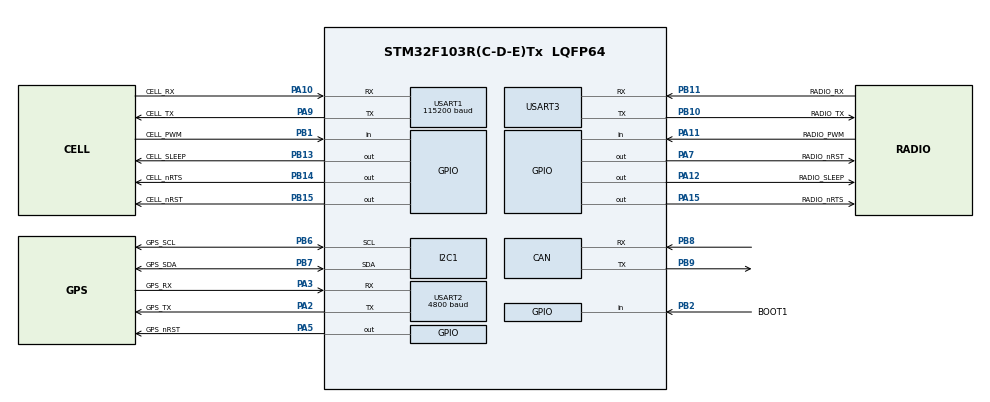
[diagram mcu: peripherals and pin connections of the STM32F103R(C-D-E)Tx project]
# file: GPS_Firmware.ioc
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CAN.CalculateTimeBit=6000
CAN.CalculateTimeQuantum=2000.0
I2C1.DualAddressMode=I2C_DUALADDRESS_DISABLE
Mcu.Family=STM32F1
Mcu.Name=STM32F103R(C-D-E)Tx
Mcu.Package=LQFP64
NVIC.PriorityGroup=NVIC_PRIORITYGROUP_4
PA10.GPIO_Label=CELL_RX
PA10.Mode=Asynchronous
PA10.Signal=USART1_RX
PA11.GPIO_Label=RADIO_PWM
PA11.Signal=GPIO_Input
PA12.GPIO_Label=RADIO_SLEEP
PA12.Signal=GPIO_Output
PA13.GPIO_Label=SWDIO
PA13.Mode=Serial_Wire
PA13.Signal=SYS_JTMS-SWDIO
PA14.GPIO_Label=SWDCLK
PA14.Mode=Serial_Wire
PA14.Signal=SYS_JTCK-SWCLK
PA15.GPIO_Label=RADIO_nRTS
PA15.Signal=GPIO_Output
PA2.GPIO_Label=GPS_TX
PA2.Mode=Asynchronous
PA2.Signal=USART2_TX
PA3.GPIO_Label=GPS_RX
PA3.Mode=Asynchronous
PA3.Signal=USART2_RX
PA5.GPIO_Label=GPS_nRST
PA5.Signal=GPIO_Output
PA7.GPIO_Label=RADIO_nRST
PA7.Signal=GPIO_Output
PA9.GPIO_Label=CELL_TX
PA9.Mode=Asynchronous
PA9.Signal=USART1_TX
PB1.GPIO_Label=CELL_PWM
PB1.Signal=GPIO_Input
PB10.GPIO_Label=RADIO_TX
PB10.Mode=Asynchronous
PB10.Signal=USART3_TX
PB11.GPIO_Label=RADIO_RX
PB11.Mode=Asynchronous
PB11.Signal=USART3_RX
PB13.GPIO_Label=CELL_SLEEP
PB13.Signal=GPIO_Output
PB14.GPIO_Label=CELL_nRTS
PB14.Signal=GPIO_Output
PB15.GPIO_Label=CELL_nRST
PB15.Signal=GPIO_Output
PB2.GPIO_Label=BOOT1
PB2.Signal=GPIO_Input
PB6.GPIO_Label=GPS_SCL
PB6.Mode=I2C
PB6.Signal=I2C1_SCL
PB7.GPIO_Label=GPS_SDA
PB7.Mode=I2C
PB7.Signal=I2C1_SDA
PB8.Mode=Master
PB8.Signal=CAN_RX
PB9.Mode=Master
PB9.Signal=CAN_TX
PC14-OSC32_IN.Signal=RCC_OSC32_IN
PC15-OSC32_OUT.Signal=RCC_OSC32_OUT
PD0-OSC_IN.Signal=RCC_OSC_IN
PD1-OSC_OUT.Signal=RCC_OSC_OUT
ProjectManager.HeapSize=0x200
ProjectManager.StackSize=0x400
ProjectManager.TargetToolchain=STM32CubeIDE
RCC.APB1Freq_Value=8000000
RCC.APB2Freq_Value=8000000
USART1.BaudRate=115200
USART1.Mode=MODE_TX_RX
USART1.StopBits=STOPBITS_1
USART1.VirtualMode=VM_ASYNC
USART1.WordLength=WORDLENGTH_8B
USART2.BaudRate=4800
USART2.VirtualMode=VM_ASYNC
USART2.WordLength=WORDLENGTH_8B
USART3.VirtualMode=VM_ASYNC
board=custom

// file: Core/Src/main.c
/* USER CODE BEGIN Header */
/**
  ******************************************************************************
  * @file           : main.c
  * @brief          : Main program body
  ******************************************************************************
  * @attention
  *
  * <h2><center>&copy; Copyright (c) 2021 STMicroelectronics.
  * All rights reserved.</center></h2>
  *
  * This software component is licensed by ST under BSD 3-Clause license,
  * the "License"; You may not use this file except in compliance with the
  * License. You may obtain a copy of the License at:
  *                        opensource.org/licenses/BSD-3-Clause
  *
  ******************************************************************************
  */
/* USER CODE END Header */
#include "main.h"
#include "stdio.h"
#include "string.h"
#include "stdbool.h"
#include "time.h"

CAN_HandleTypeDef hcan;

I2C_HandleTypeDef hi2c1;

UART_HandleTypeDef huart1;
UART_HandleTypeDef huart2;
UART_HandleTypeDef huart3;

/* USER CODE BEGIN PV */
CAN_RxHeaderTypeDef rxheader; //header for message reception
HAL_StatusTypeDef send_ret; //status return for CAN transmit

uint8_t CAN_buffer; // CAN buffer
uint8_t UART_buffer; // UART buffer

/* USER CODE END PV */

void SystemClock_Config(void);
static void MX_GPIO_Init(void);
static void MX_CAN_Init(void);
static void MX_I2C1_Init(void);
static void MX_USART1_UART_Init(void);
static void MX_USART2_UART_Init(void);
static void MX_USART3_UART_Init(void);

int main(void)
{

  /* MCU Configuration--------------------------------------------------------*/

  /* Reset of all peripherals, Initializes the Flash interface and the Systick. */
  HAL_Init();

  /* Configure the system clock */
  SystemClock_Config();

  /* Initialize all configured peripherals */
  MX_GPIO_Init();
  MX_CAN_Init();
  MX_I2C1_Init();
  MX_USART1_UART_Init();
  MX_USART2_UART_Init();
  MX_USART3_UART_Init();

  /* USER CODE BEGIN 2 */
  int can_counter;
  int timer_counter;
  time_t start_time = time(NULL); //get start time
  time_t current_time;
  timer_counter = 0;

  /* USER CODE END 2 */

  /* Infinite loop */
  while (1)
  {
    can_counter = 0;
	  //monitor CAN FIFO -> if messages, empty 3 messages from FIFO *dependent on timing/how many messages are expected*
	  while(can_counter < MAX_CAN_MESSAGES) //get CAN data
	  {
		  can_Process(&hcan,&CAN.r.rxheader,CAN.r.ret);
		  if (CAN.msgpointer != NULL)
		  {
			  xbee_Process(&huart3,&CAN.msgpointer);
			  xbee_Process(&huart1,&CAN.msgpointer);
		  }
		  else{break;}
	  }
	  //AMU
	  if(time(NULL) >= start_time+1000) //every 1 second
	  {
		  //receive AMU data
		  xbee_Process(&huart3,&CAN.msgpointer); //change to AMU data pointer
		  xbee_Process(&huart1,&CAN.msgpointer); //change to AMU data pointer
      start_time = time(NULL);
      timer_counter++;
	  }

    //GPS receive and transmit - sample every 1min *dependent on time it takes to get data/timing of CAN block*
    if(timer_counter >= 6)
    {
      gps_Init(&huart2);
      gps_Process(&huart2);
      xbee_Process(&huart3,&GPS.to_output);
      xbee_Process(&huart1,&GPS.to_output);
      timer_counter = 0;
    }

  }
}

void SystemClock_Config(void)
{
  RCC_OscInitTypeDef RCC_OscInitStruct = {0};
  RCC_ClkInitTypeDef RCC_ClkInitStruct = {0};

  /** Initializes the RCC Oscillators according to the specified parameters
  * in the RCC_OscInitTypeDef structure.
  */
  RCC_OscInitStruct.OscillatorType = RCC_OSCILLATORTYPE_HSI;
  RCC_OscInitStruct.HSIState = RCC_HSI_ON;
  RCC_OscInitStruct.HSICalibrationValue = RCC_HSICALIBRATION_DEFAULT;
  RCC_OscInitStruct.PLL.PLLState = RCC_PLL_NONE;
  if (HAL_RCC_OscConfig(&RCC_OscInitStruct) != HAL_OK)
  {
    Error_Handler();
  }
  /** Initializes the CPU, AHB and APB buses clocks
  */
  RCC_ClkInitStruct.ClockType = RCC_CLOCKTYPE_HCLK|RCC_CLOCKTYPE_SYSCLK
                              |RCC_CLOCKTYPE_PCLK1|RCC_CLOCKTYPE_PCLK2;
  RCC_ClkInitStruct.SYSCLKSource = RCC_SYSCLKSOURCE_HSI;
  RCC_ClkInitStruct.AHBCLKDivider = RCC_SYSCLK_DIV1;
  RCC_ClkInitStruct.APB1CLKDivider = RCC_HCLK_DIV1;
  RCC_ClkInitStruct.APB2CLKDivider = RCC_HCLK_DIV1;

  if (HAL_RCC_ClockConfig(&RCC_ClkInitStruct, FLASH_LATENCY_0) != HAL_OK)
  {
    Error_Handler();
  }
}

static void MX_CAN_Init(void)
{

  hcan.Instance = CAN1;
  hcan.Init.Prescaler = 16;
  hcan.Init.Mode = CAN_MODE_NORMAL;
  hcan.Init.SyncJumpWidth = CAN_SJW_1TQ;
  hcan.Init.TimeSeg1 = CAN_BS1_1TQ;
  hcan.Init.TimeSeg2 = CAN_BS2_1TQ;
  hcan.Init.TimeTriggeredMode = DISABLE;
  hcan.Init.AutoBusOff = DISABLE;
  hcan.Init.AutoWakeUp = DISABLE;
  hcan.Init.AutoRetransmission = DISABLE;
  hcan.Init.ReceiveFifoLocked = DISABLE;
  hcan.Init.TransmitFifoPriority = DISABLE;
  if (HAL_CAN_Init(&hcan) != HAL_OK)
  {
    Error_Handler();
  }

}

static void MX_I2C1_Init(void)
{

  hi2c1.Instance = I2C1;
  hi2c1.Init.ClockSpeed = 100000;
  hi2c1.Init.DutyCycle = I2C_DUTYCYCLE_2;
  hi2c1.Init.OwnAddress1 = 0;
  hi2c1.Init.AddressingMode = I2C_ADDRESSINGMODE_7BIT;
  hi2c1.Init.DualAddressMode = I2C_DUALADDRESS_DISABLE;
  hi2c1.Init.OwnAddress2 = 0;
  hi2c1.Init.GeneralCallMode = I2C_GENERALCALL_DISABLE;
  hi2c1.Init.NoStretchMode = I2C_NOSTRETCH_DISABLE;
  if (HAL_I2C_Init(&hi2c1) != HAL_OK)
  {
    Error_Handler();
  }

}

static void MX_USART1_UART_Init(void)
{

  huart1.Instance = USART1;
  huart1.Init.BaudRate = 115200;
  huart1.Init.WordLength = UART_WORDLENGTH_8B;
  huart1.Init.StopBits = UART_STOPBITS_1;
  huart1.Init.Parity = UART_PARITY_NONE;
  huart1.Init.Mode = UART_MODE_TX_RX;
  huart1.Init.HwFlowCtl = UART_HWCONTROL_NONE;
  huart1.Init.OverSampling = UART_OVERSAMPLING_16;
  if (HAL_UART_Init(&huart1) != HAL_OK)
  {
    Error_Handler();
  }

}

static void MX_USART2_UART_Init(void)
{

  huart2.Instance = USART2;
  huart2.Init.BaudRate = 4800;
  huart2.Init.WordLength = UART_WORDLENGTH_8B;
  huart2.Init.StopBits = UART_STOPBITS_1;
  huart2.Init.Parity = UART_PARITY_NONE;
  huart2.Init.Mode = UART_MODE_TX_RX;
  huart2.Init.HwFlowCtl = UART_HWCONTROL_NONE;
  huart2.Init.OverSampling = UART_OVERSAMPLING_16;
  if (HAL_UART_Init(&huart2) != HAL_OK)
  {
    Error_Handler();
  }

}

static void MX_USART3_UART_Init(void)
{

  huart3.Instance = USART3;
  huart3.Init.BaudRate = 115200;
  huart3.Init.WordLength = UART_WORDLENGTH_8B;
  huart3.Init.StopBits = UART_STOPBITS_1;
  huart3.Init.Parity = UART_PARITY_NONE;
  huart3.Init.Mode = UART_MODE_TX_RX;
  huart3.Init.HwFlowCtl = UART_HWCONTROL_NONE;
  huart3.Init.OverSampling = UART_OVERSAMPLING_16;
  if (HAL_UART_Init(&huart3) != HAL_OK)
  {
    Error_Handler();
  }

}

static void MX_GPIO_Init(void)
{
  GPIO_InitTypeDef GPIO_InitStruct = {0};

  /* GPIO Ports Clock Enable */
  __HAL_RCC_GPIOC_CLK_ENABLE();
  __HAL_RCC_GPIOD_CLK_ENABLE();
  __HAL_RCC_GPIOA_CLK_ENABLE();
  __HAL_RCC_GPIOB_CLK_ENABLE();

  /*Configure GPIO pin Output Level */
  HAL_GPIO_WritePin(GPIOA, GPS_nRST_Pin|RADIO_nRST_Pin|RADIO_SLEEP_Pin|RADIO_nRTS_Pin, GPIO_PIN_RESET);

  /*Configure GPIO pin Output Level */
  HAL_GPIO_WritePin(GPIOB, CELL_SLEEP_Pin|CELL_nRTS_Pin|CELL_nRST_Pin, GPIO_PIN_RESET);

  /*Configure GPIO pins : GPS_nRST_Pin RADIO_nRST_Pin RADIO_SLEEP_Pin RADIO_nRTS_Pin */
  GPIO_InitStruct.Pin = GPS_nRST_Pin|RADIO_nRST_Pin|RADIO_SLEEP_Pin|RADIO_nRTS_Pin;
  GPIO_InitStruct.Mode = GPIO_MODE_OUTPUT_PP;
  GPIO_InitStruct.Pull = GPIO_NOPULL;
  GPIO_InitStruct.Speed = GPIO_SPEED_FREQ_LOW;
  HAL_GPIO_Init(GPIOA, &GPIO_InitStruct);

  /*Configure GPIO pins : CELL_PWM_Pin BOOT1_Pin */
  GPIO_InitStruct.Pin = CELL_PWM_Pin|BOOT1_Pin;
  GPIO_InitStruct.Mode = GPIO_MODE_INPUT;
  GPIO_InitStruct.Pull = GPIO_NOPULL;
  HAL_GPIO_Init(GPIOB, &GPIO_InitStruct);

  /*Configure GPIO pins : CELL_SLEEP_Pin CELL_nRTS_Pin CELL_nRST_Pin */
  GPIO_InitStruct.Pin = CELL_SLEEP_Pin|CELL_nRTS_Pin|CELL_nRST_Pin;
  GPIO_InitStruct.Mode = GPIO_MODE_OUTPUT_PP;
  GPIO_InitStruct.Pull = GPIO_NOPULL;
  GPIO_InitStruct.Speed = GPIO_SPEED_FREQ_LOW;
  HAL_GPIO_Init(GPIOB, &GPIO_InitStruct);

  /*Configure GPIO pin : RADIO_PWM_Pin */
  GPIO_InitStruct.Pin = RADIO_PWM_Pin;
  GPIO_InitStruct.Mode = GPIO_MODE_INPUT;
  GPIO_InitStruct.Pull = GPIO_NOPULL;
  HAL_GPIO_Init(RADIO_PWM_GPIO_Port, &GPIO_InitStruct);

}
/* USER CODE BEGIN 4 */

//interupt for gps callback
void HAL_UART_RxCpltCallback(UART_HandleTypeDef *huart)
{
	gps_CallBack(&huart1);
}

/* USER CODE END 4 */

void Error_Handler(void)
{
}

/************************ (C) COPYRIGHT STMicroelectronics *****END OF FILE****/
